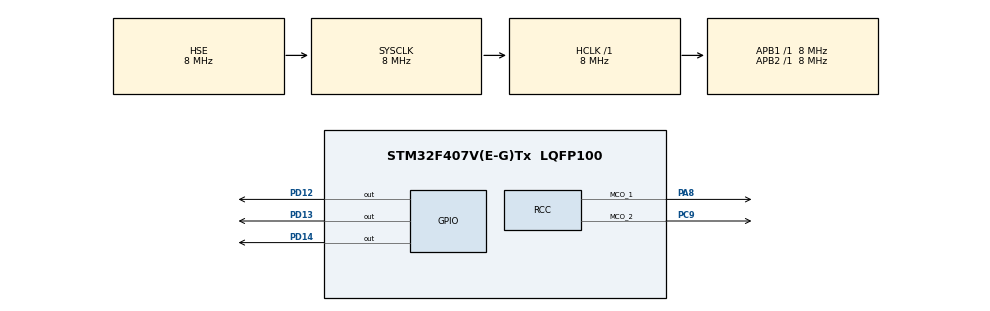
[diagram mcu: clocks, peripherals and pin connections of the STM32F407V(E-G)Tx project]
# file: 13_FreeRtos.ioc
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FREERTOS.INCLUDE_vTaskDelayUntil=1
FREERTOS.Tasks01=defaultTask,-1,128,StartDefaultTask,Default,NULL,Dynamic,NULL,NULL;Task2,0,128,Task_Init2,Default,NULL,Dynamic,NULL,NULL;Task3,1,128,Task_Init3,Default,NULL,Dynamic,NULL,NULL
FREERTOS.configUSE_NEWLIB_REENTRANT=1
Mcu.Family=STM32F4
Mcu.Name=STM32F407V(E-G)Tx
Mcu.Package=LQFP100
NVIC.PriorityGroup=NVIC_PRIORITYGROUP_4
NVIC.TIM1_UP_TIM10_IRQn=true\:15\:0\:false\:false\:true\:false\:false\:true\:true
NVIC.TimeBase=TIM1_UP_TIM10_IRQn
NVIC.TimeBaseIP=TIM1
PA13.Mode=Serial_Wire
PA13.Signal=SYS_JTMS-SWDIO
PA14.Mode=Serial_Wire
PA14.Signal=SYS_JTCK-SWCLK
PA8.Mode=Clock-out-1
PA8.Signal=RCC_MCO_1
PC9.Mode=Clock-out-2
PC9.Signal=RCC_MCO_2
PD12.Signal=GPIO_Output
PD13.Signal=GPIO_Output
PD14.Signal=GPIO_Output
PH0-OSC_IN.Mode=HSE-External-Oscillator
PH0-OSC_IN.Signal=RCC_OSC_IN
PH1-OSC_OUT.Mode=HSE-External-Oscillator
PH1-OSC_OUT.Signal=RCC_OSC_OUT
ProjectManager.HeapSize=0x200
ProjectManager.StackSize=0x400
ProjectManager.TargetToolchain=STM32CubeIDE
RCC.48MHZClocksFreq_Value=48000000
RCC.AHBFreq_Value=8000000
RCC.APB1Freq_Value=8000000
RCC.APB1TimFreq_Value=8000000
RCC.APB2Freq_Value=8000000
RCC.APB2TimFreq_Value=8000000
RCC.CortexFreq_Value=8000000
RCC.HCLKFreq_Value=8000000
RCC.HSE_VALUE=8000000
RCC.HSI_VALUE=16000000
RCC.LSE_VALUE=32768
RCC.SYSCLKFreq_VALUE=8000000
RCC.SYSCLKSource=RCC_SYSCLKSOURCE_HSE
RCC.VCOOutputFreq_Value=192000000
VP_FREERTOS_VS_CMSIS_V1.Mode=CMSIS_V1
VP_SYS_VS_tim1.Mode=TIM1
board=custom

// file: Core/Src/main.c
/* USER CODE BEGIN Header */
/**
  ******************************************************************************
  * @file           : main.c
  * @brief          : Main program body
  ******************************************************************************
  * @attention
  *
  * Copyright (c) 2023 STMicroelectronics.
  * All rights reserved.
  *
  * This software is licensed under terms that can be found in the LICENSE file
  * in the root directory of this software component.
  * If no LICENSE file comes with this software, it is provided AS-IS.
  *
  ******************************************************************************
  */
/* USER CODE END Header */
#include "main.h"
#include "cmsis_os.h"

/* USER CODE BEGIN Includes */
#include "stdio.h"
/* USER CODE END Includes */

osThreadId defaultTaskHandle;
osThreadId Task2Handle;
osThreadId Task3Handle;

void SystemClock_Config(void);
static void MX_GPIO_Init(void);
void StartDefaultTask(void const * argument);
void Task_Init2(void const * argument);
void Task_Init3(void const * argument);

/* USER CODE BEGIN PFP */
uint8_t indx;
/* USER CODE END PFP */

/* USER CODE BEGIN 0 */
osThreadId Task2Handler;
/* USER CODE END 0 */

int main(void)
{

  /* MCU Configuration--------------------------------------------------------*/

  /* Reset of all peripherals, Initializes the Flash interface and the Systick. */
  HAL_Init();

  /* Configure the system clock */
  SystemClock_Config();

  /* Initialize all configured peripherals */
  MX_GPIO_Init();

  /* Create the thread(s) */
  /* definition and creation of defaultTask */
  osThreadDef(defaultTask, StartDefaultTask, osPriorityBelowNormal, 0, 128);
  defaultTaskHandle = osThreadCreate(osThread(defaultTask), NULL);

  /* definition and creation of Task2 */
  osThreadDef(Task2, Task_Init2, osPriorityNormal, 0, 128);
  Task2Handle = osThreadCreate(osThread(Task2), NULL);

  /* definition and creation of Task3 */
  osThreadDef(Task3, Task_Init3, osPriorityAboveNormal, 0, 128);
  Task3Handle = osThreadCreate(osThread(Task3), NULL);

  /* Start scheduler */
  osKernelStart();

  /* We should never get here as control is now taken by the scheduler */

  /* Infinite loop */
  while (1)
  {

  }
}

void SystemClock_Config(void)
{
  RCC_OscInitTypeDef RCC_OscInitStruct = {0};
  RCC_ClkInitTypeDef RCC_ClkInitStruct = {0};

  /** Configure the main internal regulator output voltage
  */
  __HAL_RCC_PWR_CLK_ENABLE();
  __HAL_PWR_VOLTAGESCALING_CONFIG(PWR_REGULATOR_VOLTAGE_SCALE1);

  /** Initializes the RCC Oscillators according to the specified parameters
  * in the RCC_OscInitTypeDef structure.
  */
  RCC_OscInitStruct.OscillatorType = RCC_OSCILLATORTYPE_HSI|RCC_OSCILLATORTYPE_HSE;
  RCC_OscInitStruct.HSEState = RCC_HSE_ON;
  RCC_OscInitStruct.HSIState = RCC_HSI_ON;
  RCC_OscInitStruct.HSICalibrationValue = RCC_HSICALIBRATION_DEFAULT;
  RCC_OscInitStruct.PLL.PLLState = RCC_PLL_NONE;
  if (HAL_RCC_OscConfig(&RCC_OscInitStruct) != HAL_OK)
  {
    Error_Handler();
  }

  /** Initializes the CPU, AHB and APB buses clocks
  */
  RCC_ClkInitStruct.ClockType = RCC_CLOCKTYPE_HCLK|RCC_CLOCKTYPE_SYSCLK
                              |RCC_CLOCKTYPE_PCLK1|RCC_CLOCKTYPE_PCLK2;
  RCC_ClkInitStruct.SYSCLKSource = RCC_SYSCLKSOURCE_HSE;
  RCC_ClkInitStruct.AHBCLKDivider = RCC_SYSCLK_DIV1;
  RCC_ClkInitStruct.APB1CLKDivider = RCC_HCLK_DIV1;
  RCC_ClkInitStruct.APB2CLKDivider = RCC_HCLK_DIV1;

  if (HAL_RCC_ClockConfig(&RCC_ClkInitStruct, FLASH_LATENCY_0) != HAL_OK)
  {
    Error_Handler();
  }
  HAL_RCC_MCOConfig(RCC_MCO1, RCC_MCO1SOURCE_HSI, RCC_MCODIV_1);
  HAL_RCC_MCOConfig(RCC_MCO2, RCC_MCO2SOURCE_SYSCLK, RCC_MCODIV_1);
}

static void MX_GPIO_Init(void)
{
  GPIO_InitTypeDef GPIO_InitStruct = {0};

  /* GPIO Ports Clock Enable */
  __HAL_RCC_GPIOH_CLK_ENABLE();
  __HAL_RCC_GPIOD_CLK_ENABLE();
  __HAL_RCC_GPIOC_CLK_ENABLE();
  __HAL_RCC_GPIOA_CLK_ENABLE();

  /*Configure GPIO pin Output Level */
  HAL_GPIO_WritePin(GPIOD, GPIO_PIN_12|GPIO_PIN_13|GPIO_PIN_14, GPIO_PIN_RESET);

  /*Configure GPIO pins : PD12 PD13 PD14 */
  GPIO_InitStruct.Pin = GPIO_PIN_12|GPIO_PIN_13|GPIO_PIN_14;
  GPIO_InitStruct.Mode = GPIO_MODE_OUTPUT_PP;
  GPIO_InitStruct.Pull = GPIO_NOPULL;
  GPIO_InitStruct.Speed = GPIO_SPEED_FREQ_LOW;
  HAL_GPIO_Init(GPIOD, &GPIO_InitStruct);

  /*Configure GPIO pin : PC9 */
  GPIO_InitStruct.Pin = GPIO_PIN_9;
  GPIO_InitStruct.Mode = GPIO_MODE_AF_PP;
  GPIO_InitStruct.Pull = GPIO_NOPULL;
  GPIO_InitStruct.Speed = GPIO_SPEED_FREQ_LOW;
  GPIO_InitStruct.Alternate = GPIO_AF0_MCO;
  HAL_GPIO_Init(GPIOC, &GPIO_InitStruct);

  /*Configure GPIO pin : PA8 */
  GPIO_InitStruct.Pin = GPIO_PIN_8;
  GPIO_InitStruct.Mode = GPIO_MODE_AF_PP;
  GPIO_InitStruct.Pull = GPIO_NOPULL;
  GPIO_InitStruct.Speed = GPIO_SPEED_FREQ_LOW;
  GPIO_InitStruct.Alternate = GPIO_AF0_MCO;
  HAL_GPIO_Init(GPIOA, &GPIO_InitStruct);

}

void StartDefaultTask(void const * argument)
{
  /* USER CODE BEGIN 5 */
  /* Infinite loop */
  for(;;)
  {
    HAL_GPIO_TogglePin(GPIOD, GPIO_PIN_12);
    osDelay(1000);
  }
  /* USER CODE END 5 */
}

void Task_Init2(void const * argument)
{
  /* USER CODE BEGIN Task_Init2 */
  /* Infinite loop */
  for(;;)
  {
    HAL_GPIO_TogglePin(GPIOD, GPIO_PIN_13);
	osDelay(1000);
  }
  /* USER CODE END Task_Init2 */
}

void Task_Init3(void const * argument)
{
  /* USER CODE BEGIN Task_Init3 */
  /* Infinite loop */
  for(;;)
  {
	HAL_GPIO_TogglePin(GPIOD, GPIO_PIN_14);
    osDelay(1000);
  }
  /* USER CODE END Task_Init3 */
}

void HAL_TIM_PeriodElapsedCallback(TIM_HandleTypeDef *htim)
{
  if (htim->Instance == TIM1) {
    HAL_IncTick();
  }
}

void Error_Handler(void)
{
  __disable_irq();
  while (1)
  {
  }
}
